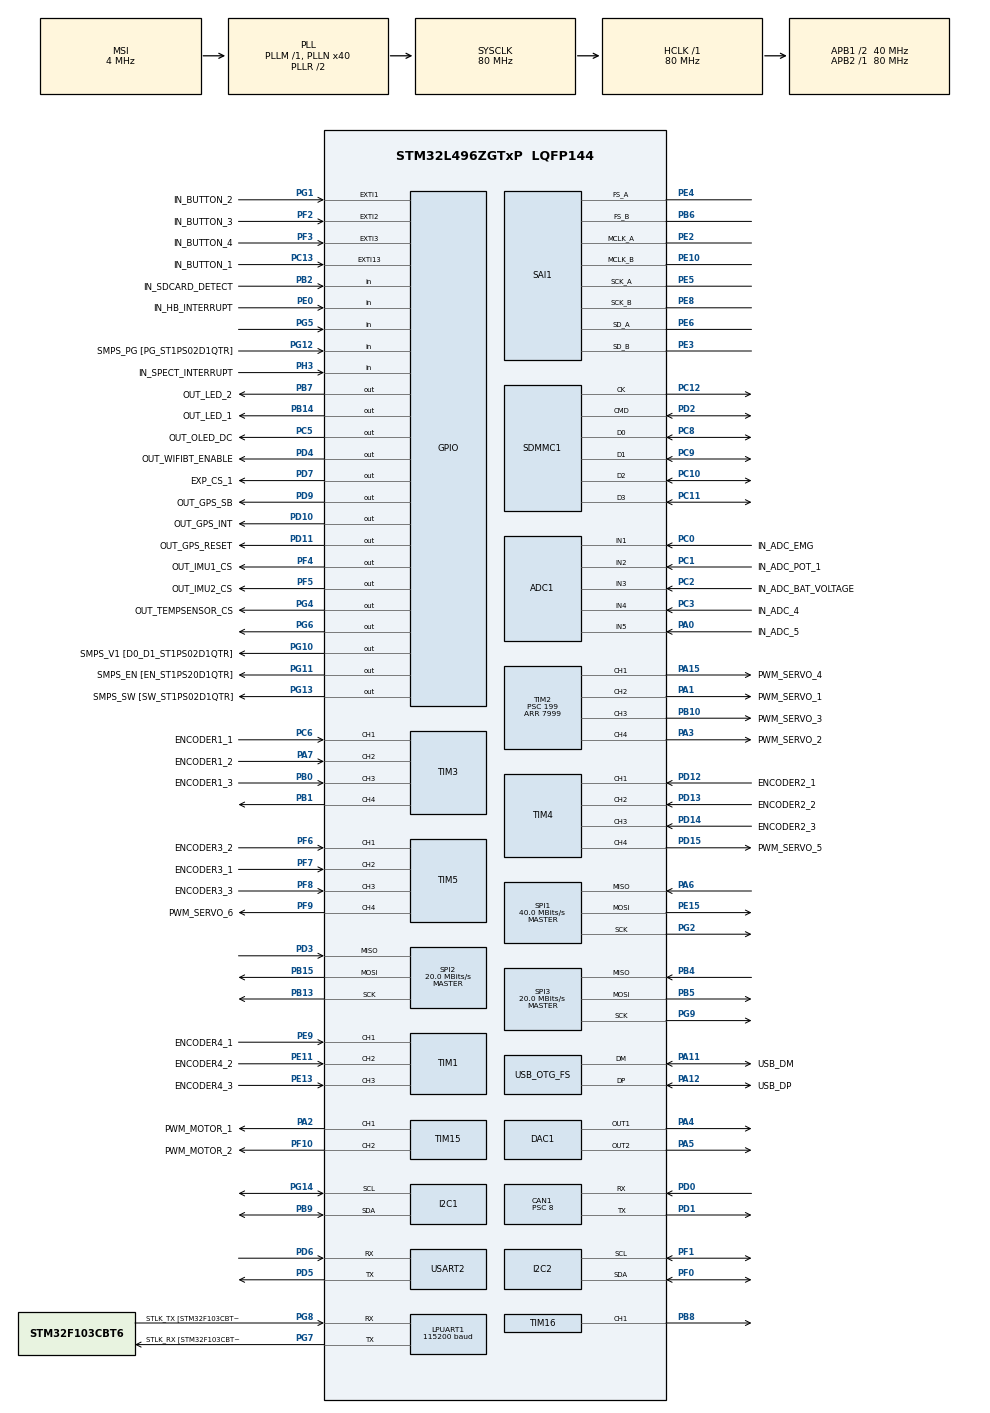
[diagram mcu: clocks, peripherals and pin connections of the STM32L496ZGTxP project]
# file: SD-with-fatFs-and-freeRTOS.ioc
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ADC1.Channel-0\#ChannelRegularConversion=ADC_CHANNEL_2
ADC1.Channel-1\#ChannelRegularConversion=ADC_CHANNEL_5
ADC1.Channel-2\#ChannelRegularConversion=ADC_CHANNEL_1
ADC1.Channel-3\#ChannelRegularConversion=ADC_CHANNEL_4
ADC1.Channel-4\#ChannelRegularConversion=ADC_CHANNEL_3
ADC1.ContinuousConvMode=ENABLE
ADC1.EOCSelection=ADC_EOC_SEQ_CONV
ADC1.NbrOfConversion=5
ADC1.NbrOfConversionFlag=1
ADC1.OffsetNumber-0\#ChannelRegularConversion=ADC_OFFSET_NONE
ADC1.OffsetNumber-1\#ChannelRegularConversion=ADC_OFFSET_NONE
ADC1.OffsetNumber-2\#ChannelRegularConversion=ADC_OFFSET_NONE
ADC1.OffsetNumber-3\#ChannelRegularConversion=ADC_OFFSET_NONE
ADC1.OffsetNumber-4\#ChannelRegularConversion=ADC_OFFSET_NONE
ADC1.OversamplingMode=ENABLE
ADC1.Rank-0\#ChannelRegularConversion=1
ADC1.Rank-1\#ChannelRegularConversion=2
ADC1.Rank-2\#ChannelRegularConversion=3
ADC1.Rank-3\#ChannelRegularConversion=4
ADC1.Rank-4\#ChannelRegularConversion=5
ADC1.Ratio=ADC_OVERSAMPLING_RATIO_8
ADC1.RightBitShift=ADC_RIGHTBITSHIFT_3
ADC1.SamplingTime-0\#ChannelRegularConversion=ADC_SAMPLETIME_2CYCLES_5
ADC1.SamplingTime-1\#ChannelRegularConversion=ADC_SAMPLETIME_2CYCLES_5
ADC1.SamplingTime-2\#ChannelRegularConversion=ADC_SAMPLETIME_2CYCLES_5
ADC1.SamplingTime-3\#ChannelRegularConversion=ADC_SAMPLETIME_2CYCLES_5
ADC1.SamplingTime-4\#ChannelRegularConversion=ADC_SAMPLETIME_2CYCLES_5
ADC1.master=1
CAN1.BS1=CAN_BS1_2TQ
CAN1.BS2=CAN_BS2_2TQ
CAN1.CalculateBaudRate=1000000
CAN1.CalculateTimeBit=1000
CAN1.CalculateTimeQuantum=200.0
CAN1.Prescaler=8
DAC1.DAC_Channel-DAC_OUT2=DAC_CHANNEL_2
Dma.ADC1.4.Direction=DMA_PERIPH_TO_MEMORY
Dma.ADC1.4.Instance=DMA1_Channel1
Dma.ADC1.4.MemDataAlignment=DMA_MDATAALIGN_WORD
Dma.ADC1.4.MemInc=DMA_MINC_ENABLE
Dma.ADC1.4.Mode=DMA_CIRCULAR
Dma.ADC1.4.PeriphDataAlignment=DMA_PDATAALIGN_WORD
Dma.ADC1.4.PeriphInc=DMA_PINC_DISABLE
Dma.ADC1.4.Priority=DMA_PRIORITY_LOW
Dma.Request0=SPI1_RX
Dma.Request1=SPI1_TX
Dma.Request2=SPI2_RX
Dma.Request3=SPI2_TX
Dma.Request4=ADC1
Dma.Request5=SDMMC1
Dma.SDMMC1.5.Direction=DMA_PERIPH_TO_MEMORY
Dma.SDMMC1.5.Instance=DMA2_Channel4
Dma.SDMMC1.5.MemDataAlignment=DMA_MDATAALIGN_WORD
Dma.SDMMC1.5.MemInc=DMA_MINC_ENABLE
Dma.SDMMC1.5.Mode=DMA_NORMAL
Dma.SDMMC1.5.PeriphDataAlignment=DMA_PDATAALIGN_WORD
Dma.SDMMC1.5.PeriphInc=DMA_PINC_DISABLE
Dma.SDMMC1.5.Priority=DMA_PRIORITY_LOW
Dma.SPI1_RX.0.Direction=DMA_PERIPH_TO_MEMORY
Dma.SPI1_RX.0.Instance=DMA1_Channel2
Dma.SPI1_RX.0.MemDataAlignment=DMA_MDATAALIGN_BYTE
Dma.SPI1_RX.0.MemInc=DMA_MINC_ENABLE
Dma.SPI1_RX.0.Mode=DMA_NORMAL
Dma.SPI1_RX.0.PeriphDataAlignment=DMA_PDATAALIGN_BYTE
Dma.SPI1_RX.0.PeriphInc=DMA_PINC_DISABLE
Dma.SPI1_RX.0.Priority=DMA_PRIORITY_LOW
Dma.SPI1_TX.1.Direction=DMA_MEMORY_TO_PERIPH
Dma.SPI1_TX.1.Instance=DMA1_Channel3
Dma.SPI1_TX.1.MemDataAlignment=DMA_MDATAALIGN_BYTE
Dma.SPI1_TX.1.MemInc=DMA_MINC_ENABLE
Dma.SPI1_TX.1.Mode=DMA_NORMAL
Dma.SPI1_TX.1.PeriphDataAlignment=DMA_PDATAALIGN_BYTE
Dma.SPI1_TX.1.PeriphInc=DMA_PINC_DISABLE
Dma.SPI1_TX.1.Priority=DMA_PRIORITY_LOW
Dma.SPI2_RX.2.Direction=DMA_PERIPH_TO_MEMORY
Dma.SPI2_RX.2.Instance=DMA1_Channel4
Dma.SPI2_RX.2.MemDataAlignment=DMA_MDATAALIGN_BYTE
Dma.SPI2_RX.2.MemInc=DMA_MINC_ENABLE
Dma.SPI2_RX.2.Mode=DMA_NORMAL
Dma.SPI2_RX.2.PeriphDataAlignment=DMA_PDATAALIGN_BYTE
Dma.SPI2_RX.2.PeriphInc=DMA_PINC_DISABLE
Dma.SPI2_RX.2.Priority=DMA_PRIORITY_LOW
Dma.SPI2_TX.3.Direction=DMA_MEMORY_TO_PERIPH
Dma.SPI2_TX.3.Instance=DMA1_Channel5
Dma.SPI2_TX.3.MemDataAlignment=DMA_MDATAALIGN_BYTE
Dma.SPI2_TX.3.MemInc=DMA_MINC_ENABLE
Dma.SPI2_TX.3.Mode=DMA_NORMAL
Dma.SPI2_TX.3.PeriphDataAlignment=DMA_PDATAALIGN_BYTE
Dma.SPI2_TX.3.PeriphInc=DMA_PINC_DISABLE
Dma.SPI2_TX.3.Priority=DMA_PRIORITY_LOW
FATFS.BSP.number=1
FATFS.USE_DMA_CODE_SD=1
FATFS._FS_RPATH=2
FATFS._USE_FIND=1
FATFS._USE_LFN=1
FATFS0.BSP.STBoard=false
FATFS0.BSP.api=Unknown
FATFS0.BSP.i2caddr=0
FATFS0.BSP.instance=PB2
FATFS0.BSP.ip=GPIO
FATFS0.BSP.mode=Input
FATFS0.BSP.name=Detect_SDIO
FATFS0.BSP.solution=PB2
I2C1.Timing=0x00909BEB
I2C2.Timing=0x00909BEB
LPUART1.BaudRate=115200
LPUART1.WordLength=UART_WORDLENGTH_8B
Mcu.Family=STM32L4
Mcu.Name=STM32L496ZGTxP
Mcu.Package=LQFP144
NVIC.CAN1_RX0_IRQn=true\:0\:0\:false\:false\:true\:true\:true
NVIC.DMA1_Channel1_IRQn=true\:0\:0\:false\:false\:true\:false\:true
NVIC.DMA1_Channel2_IRQn=true\:0\:0\:false\:false\:true\:false\:true
NVIC.DMA1_Channel3_IRQn=true\:0\:0\:false\:false\:true\:false\:true
NVIC.DMA1_Channel4_IRQn=true\:0\:0\:false\:false\:true\:false\:true
NVIC.DMA1_Channel5_IRQn=true\:0\:0\:false\:false\:true\:false\:true
NVIC.DMA2_Channel4_IRQn=true\:0\:0\:false\:false\:true\:false\:true
NVIC.EXTI15_10_IRQn=true\:0\:0\:false\:false\:true\:true\:true
NVIC.LPUART1_IRQn=true\:0\:0\:false\:false\:true\:true\:true
NVIC.PriorityGroup=NVIC_PRIORITYGROUP_4
NVIC.SDMMC1_IRQn=true\:0\:0\:false\:false\:true\:true\:true
NVIC.TIM7_IRQn=true\:0\:0\:false\:false\:true\:true\:true
PA0.GPIO_Label=IN_ADC_5
PA0.Signal=ADCx_IN5
PA1.GPIO_Label=PWM_SERVO_1
PA1.Signal=S_TIM2_CH2
PA10.GPIO_Label=USB_ID
PA10.Signal=USB_OTG_FS_ID
PA11.GPIO_Label=USB_DM
PA11.Mode=Device_Only
PA11.Signal=USB_OTG_FS_DM
PA12.GPIO_Label=USB_DP
PA12.Mode=Device_Only
PA12.Signal=USB_OTG_FS_DP
PA13\ (JTMS/SWDIO).GPIO_Label=TMS
PA13\ (JTMS/SWDIO).Mode=Trace_Asynchronous_SW
PA13\ (JTMS/SWDIO).Signal=SYS_JTMS-SWDIO
PA14\ (JTCK/SWCLK).GPIO_Label=TCK
PA14\ (JTCK/SWCLK).Mode=Trace_Asynchronous_SW
PA14\ (JTCK/SWCLK).Signal=SYS_JTCK-SWCLK
PA15\ (JTDI).GPIO_Label=PWM_SERVO_4
PA15\ (JTDI).Signal=S_TIM2_CH1
PA2.GPIO_Label=PWM_MOTOR_1
PA2.Signal=S_TIM15_CH1
PA3.GPIO_Label=PWM_SERVO_2
PA3.Signal=S_TIM2_CH4
PA4.Signal=COMP_DAC11_group
PA5.Signal=COMP_DAC12_group
PA6.Mode=Full_Duplex_Master
PA6.Signal=SPI1_MISO
PA7.GPIO_Label=ENCODER1_2
PA7.Signal=S_TIM3_CH2
PA8.GPIO_Label=USB_SOF [TP1]
PA8.Signal=USB_OTG_FS_SOF
PA9.GPIO_Label=USB_VBUS
PA9.Signal=USB_OTG_FS_VBUS
PB0.GPIO_Label=ENCODER1_3
PB0.Signal=S_TIM3_CH3
PB1.Signal=S_TIM3_CH4
PB10.GPIO_Label=PWM_SERVO_3
PB10.Signal=S_TIM2_CH3
PB13.Mode=Full_Duplex_Master
PB13.Signal=SPI2_SCK
PB14.GPIO_Label=OUT_LED_1
PB14.Signal=GPIO_Output
PB15.Mode=Full_Duplex_Master
PB15.Signal=SPI2_MOSI
PB2.GPIO_Label=IN_SDCARD_DETECT
PB2.Signal=GPIO_Input
PB3\ (JTDO/TRACESWO).GPIO_Label=SWO
PB3\ (JTDO/TRACESWO).Mode=Trace_Asynchronous_SW
PB3\ (JTDO/TRACESWO).Signal=SYS_JTDO-SWO
PB4\ (NJTRST).Mode=Full_Duplex_Master
PB4\ (NJTRST).Signal=SPI3_MISO
PB5.Mode=Full_Duplex_Master
PB5.Signal=SPI3_MOSI
PB6.Mode=SAI_B_MasterWithClock
PB6.Signal=SAI1_FS_B
PB7.GPIO_Label=OUT_LED_2
PB7.Signal=GPIO_Output
PB8.Signal=S_TIM16_CH1
PB9.GPIO_Pu=GPIO_PULLUP
PB9.Mode=I2C
PB9.Signal=I2C1_SDA
PC0.GPIO_Label=IN_ADC_EMG
PC0.Signal=ADCx_IN1
PC1.GPIO_Label=IN_ADC_POT_1
PC1.Signal=ADCx_IN2
PC10.Mode=SD_4_bits_Wide_bus
PC10.Signal=SDMMC1_D2
PC11.Mode=SD_4_bits_Wide_bus
PC11.Signal=SDMMC1_D3
PC12.Mode=SD_4_bits_Wide_bus
PC12.Signal=SDMMC1_CK
PC13.GPIO_Label=IN_BUTTON_1
PC13.Signal=GPXTI13
PC14-OSC32_IN\ (PC14).Mode=LSE-External-Oscillator
PC14-OSC32_IN\ (PC14).Signal=RCC_OSC32_IN
PC15-OSC32_OUT\ (PC15).Mode=LSE-External-Oscillator
PC15-OSC32_OUT\ (PC15).Signal=RCC_OSC32_OUT
PC2.GPIO_Label=IN_ADC_BAT_VOLTAGE
PC2.GPIO_PuPd=GPIO_NOPULL
PC2.Signal=ADCx_IN3
PC3.GPIO_Label=IN_ADC_4
PC3.Signal=ADCx_IN4
PC5.GPIO_Label=OUT_OLED_DC
PC5.Signal=GPIO_Output
PC6.GPIO_Label=ENCODER1_1
PC6.Signal=S_TIM3_CH1
PC8.Mode=SD_4_bits_Wide_bus
PC8.Signal=SDMMC1_D0
PC9.Mode=SD_4_bits_Wide_bus
PC9.Signal=SDMMC1_D1
PD0.Mode=CAN_Activate
PD0.Signal=CAN1_RX
PD1.Mode=CAN_Activate
PD1.Signal=CAN1_TX
PD10.GPIO_Label=OUT_GPS_INT
PD10.Signal=GPIO_Output
PD11.GPIO_Label=OUT_GPS_RESET
PD11.Signal=GPIO_Output
PD12.GPIO_Label=ENCODER2_1
PD12.Signal=S_TIM4_CH1
PD13.GPIO_Label=ENCODER2_2
PD13.Signal=S_TIM4_CH2
PD14.GPIO_Label=ENCODER2_3
PD14.Signal=S_TIM4_CH3
PD15.GPIO_Label=PWM_SERVO_5
PD15.Signal=S_TIM4_CH4
PD2.Mode=SD_4_bits_Wide_bus
PD2.Signal=SDMMC1_CMD
PD3.Mode=Full_Duplex_Master
PD3.Signal=SPI2_MISO
PD4.GPIO_Label=OUT_WIFIBT_ENABLE
PD4.Signal=GPIO_Output
PD5.Mode=Asynchronous
PD5.Signal=USART2_TX
PD6.Mode=Asynchronous
PD6.Signal=USART2_RX
PD7.GPIO_Label=EXP_CS_1
PD7.Signal=GPIO_Output
PD9.GPIO_Label=OUT_GPS_SB
PD9.Signal=GPIO_Output
PE0.GPIO_Label=IN_HB_INTERRUPT
PE0.Signal=GPIO_Input
PE10.Mode=SAI_B_MasterWithClock
PE10.Signal=SAI1_MCLK_B
PE11.GPIO_Label=ENCODER4_2
PE11.Signal=S_TIM1_CH2
PE13.GPIO_Label=ENCODER4_3
PE13.Signal=S_TIM1_CH3
PE15.Mode=Full_Duplex_Master
PE15.Signal=SPI1_MOSI
PE2.Mode=SAI_A_MasterWithClock
PE2.Signal=SAI1_MCLK_A
PE3.Mode=SAI_B_MasterWithClock
PE3.Signal=SAI1_SD_B
PE4.Mode=SAI_A_MasterWithClock
PE4.Signal=SAI1_FS_A
PE5.Mode=SAI_A_MasterWithClock
PE5.Signal=SAI1_SCK_A
PE6.Mode=SAI_A_MasterWithClock
PE6.Signal=SAI1_SD_A
PE8.Mode=SAI_B_MasterWithClock
PE8.Signal=SAI1_SCK_B
PE9.GPIO_Label=ENCODER4_1
PE9.Signal=S_TIM1_CH1
PF0.GPIO_Pu=GPIO_PULLUP
PF0.Mode=I2C
PF0.Signal=I2C2_SDA
PF1.GPIO_Pu=GPIO_PULLUP
PF1.Mode=I2C
PF1.Signal=I2C2_SCL
PF10.GPIO_Label=PWM_MOTOR_2
PF10.Signal=S_TIM15_CH2
PF2.GPIO_Label=IN_BUTTON_3
PF2.Signal=GPXTI2
PF3.GPIO_Label=IN_BUTTON_4
PF3.Signal=GPXTI3
PF4.GPIO_Label=OUT_IMU1_CS
PF4.Signal=GPIO_Output
PF5.GPIO_Label=OUT_IMU2_CS
PF5.Signal=GPIO_Output
PF6.GPIO_Label=ENCODER3_2
PF6.Signal=S_TIM5_CH1
PF7.GPIO_Label=ENCODER3_1
PF7.Signal=S_TIM5_CH2
PF8.GPIO_Label=ENCODER3_3
PF8.Signal=S_TIM5_CH3
PF9.GPIO_Label=PWM_SERVO_6
PF9.Signal=S_TIM5_CH4
PG1.GPIO_Label=IN_BUTTON_2
PG1.Signal=GPXTI1
PG10.GPIO_Label=SMPS_V1 [D0_D1_ST1PS02D1QTR]
PG10.Signal=GPIO_Output
PG11.GPIO_Label=SMPS_EN [EN_ST1PS20D1QTR]
PG11.Signal=GPIO_Output
PG12.GPIO_Label=SMPS_PG [PG_ST1PS02D1QTR]
PG12.Signal=GPIO_Input
PG13.GPIO_Label=SMPS_SW [SW_ST1PS02D1QTR]
PG13.Signal=GPIO_Output
PG14.GPIO_Pu=GPIO_PULLUP
PG14.Mode=I2C
PG14.Signal=I2C1_SCL
PG2.Mode=Full_Duplex_Master
PG2.Signal=SPI1_SCK
PG4.GPIO_Label=OUT_TEMPSENSOR_CS
PG4.Signal=GPIO_Output
PG5.Signal=GPIO_Input
PG6.Signal=GPIO_Output
PG7.GPIO_Label=STLK_RX [STM32F103CBT6_PA3]
PG7.Mode=Asynchronous
PG7.Signal=LPUART1_TX
PG8.GPIO_Label=STLK_TX [STM32F103CBT6_PA2]
PG8.Mode=Asynchronous
PG8.Signal=LPUART1_RX
PG9.Mode=Full_Duplex_Master
PG9.Signal=SPI3_SCK
PH0-OSC_IN\ (PH0).GPIO_Label=MCO
PH0-OSC_IN\ (PH0).Signal=RCC_OSC_IN
PH1-OSC_OUT\ (PH1).Signal=RCC_OSC_OUT
PH3-BOOT0.GPIO_Label=IN_SPECT_INTERRUPT
PH3-BOOT0.Signal=GPIO_Input
ProjectManager.HeapSize=0x400
ProjectManager.StackSize=0x800
ProjectManager.TargetToolchain=STM32CubeIDE
RCC.48MHZClocksFreq_Value=24000000
RCC.ADCFreq_Value=32000000
RCC.AHBFreq_Value=80000000
RCC.APB1CLKDivider=RCC_HCLK_DIV2
RCC.APB1Freq_Value=40000000
RCC.APB1TimFreq_Value=80000000
RCC.APB2Freq_Value=80000000
RCC.APB2TimFreq_Value=80000000
RCC.CK48CLockSelection=RCC_USBCLKSOURCE_HSI48
RCC.CortexFreq_Value=80000000
RCC.HCLKFreq_Value=80000000
RCC.HSE_VALUE=8000000
RCC.HSI48_VALUE=48000000
RCC.HSI_VALUE=16000000
RCC.MSI_VALUE=4000000
RCC.PLLMUL=RCC_PLL_MUL9
RCC.PLLN=40
RCC.PLLSAI1N=16
RCC.PRESCALERUSB=RCC_USBCLKSOURCE_PLL_DIV1_5
RCC.SYSCLKFreq_VALUE=80000000
RCC.SYSCLKSource=RCC_SYSCLKSOURCE_PLLCLK
RCC.SYSCLKSourceVirtual=RCC_SYSCLKSOURCE_PLLCLK
RCC.USBFreq_Value=48000000
RCC.VCOOutputFreq_Value=160000000
SAI1.ErrorAudioFreq-SAI_A_MasterWithClock=-2.34 %
SAI1.ErrorAudioFreq-SAI_B_MasterWithClock=-2.34 %
SAI1.InitProtocol-SAI_A_MasterWithClock=Enable
SAI1.InitProtocol-SAI_B_MasterWithClock=Enable
SAI1.Instance-SAI_A_MasterWithClock=SAI$Index_Block_A
SAI1.Instance-SAI_B_MasterWithClock=SAI$Index_Block_B
SAI1.MClockEnable-SAI_A_MasterWithClock=SAI_MASTERCLOCK_ENABLE
SAI1.MClockEnable-SAI_B_MasterWithClock=SAI_MASTERCLOCK_ENABLE
SAI1.RealAudioFreq-SAI_A_MasterWithClock=187.5 KHz
SAI1.RealAudioFreq-SAI_B_MasterWithClock=187.5 KHz
SAI1.VirtualMode-SAI_A_MasterWithClock=VM_MASTER
SAI1.VirtualMode-SAI_B_MasterWithClock=VM_MASTER
SAI1.VirtualProtocol-SAI_A_BASIC=VM_BASIC_PROTOCOL
SAI1.VirtualProtocol-SAI_B_BASIC=VM_BASIC_PROTOCOL
SDMMC1.ClockDiv=2
SH.ADCx_IN1.0=ADC1_IN1,IN1-Single-Ended
SH.ADCx_IN2.0=ADC1_IN2,IN2-Single-Ended
SH.ADCx_IN3.0=ADC1_IN3,IN3-Single-Ended
SH.ADCx_IN4.0=ADC1_IN4,IN4-Single-Ended
SH.ADCx_IN5.0=ADC1_IN5,IN5-Single-Ended
SH.COMP_DAC11_group.0=DAC1_OUT1,DAC_OUT1
SH.COMP_DAC12_group.0=DAC1_OUT2,DAC_OUT2
SH.S_TIM15_CH1.0=TIM15_CH1,PWM Generation1 CH1
SH.S_TIM15_CH2.0=TIM15_CH2,PWM Generation2 CH2
SH.S_TIM16_CH1.0=TIM16_CH1,PWM Generation1 CH1
SH.S_TIM1_CH1.0=TIM1_CH1,Xored_Inputs_Hall_Sensor_Interface
SH.S_TIM1_CH2.0=TIM1_CH2,Xored_Inputs_Hall_Sensor_Interface
SH.S_TIM1_CH3.0=TIM1_CH3,Xored_Inputs_Hall_Sensor_Interface
SH.S_TIM2_CH1.0=TIM2_CH1,PWM Generation1 CH1
SH.S_TIM2_CH2.0=TIM2_CH2,PWM Generation2 CH2
SH.S_TIM2_CH3.0=TIM2_CH3,PWM Generation3 CH3
SH.S_TIM2_CH4.0=TIM2_CH4,PWM Generation4 CH4
SH.S_TIM3_CH1.0=TIM3_CH1,Xored_Inputs_Hall_Sensor_Interface
SH.S_TIM3_CH2.0=TIM3_CH2,Xored_Inputs_Hall_Sensor_Interface
SH.S_TIM3_CH3.0=TIM3_CH3,Xored_Inputs_Hall_Sensor_Interface
SH.S_TIM3_CH4.0=TIM3_CH4,PWM Generation4 CH4
SH.S_TIM4_CH1.0=TIM4_CH1,Xored_Inputs_Hall_Sensor_Interface
SH.S_TIM4_CH2.0=TIM4_CH2,Xored_Inputs_Hall_Sensor_Interface
SH.S_TIM4_CH3.0=TIM4_CH3,Xored_Inputs_Hall_Sensor_Interface
SH.S_TIM4_CH4.0=TIM4_CH4,PWM Generation4 CH4
SH.S_TIM5_CH1.0=TIM5_CH1,Xored_Inputs_Hall_Sensor_Interface
SH.S_TIM5_CH2.0=TIM5_CH2,Xored_Inputs_Hall_Sensor_Interface
SH.S_TIM5_CH3.0=TIM5_CH3,Xored_Inputs_Hall_Sensor_Interface
SH.S_TIM5_CH4.0=TIM5_CH4,PWM Generation4 CH4
SPI1.CalculateBaudRate=40.0 MBits/s
SPI1.Direction=SPI_DIRECTION_2LINES
SPI1.Mode=SPI_MODE_MASTER
SPI1.VirtualType=VM_MASTER
SPI2.CalculateBaudRate=20.0 MBits/s
SPI2.Direction=SPI_DIRECTION_2LINES
SPI2.Mode=SPI_MODE_MASTER
SPI2.VirtualType=VM_MASTER
SPI3.CalculateBaudRate=20.0 MBits/s
SPI3.Direction=SPI_DIRECTION_2LINES
SPI3.Mode=SPI_MODE_MASTER
SPI3.VirtualType=VM_MASTER
TIM15.Channel-PWM\ Generation1\ CH1=TIM_CHANNEL_1
TIM15.Channel-PWM\ Generation2\ CH2=TIM_CHANNEL_2
TIM16.Channel=TIM_CHANNEL_1
TIM2.AutoReloadPreload=TIM_AUTORELOAD_PRELOAD_DISABLE
TIM2.Channel-PWM\ Generation1\ CH1=TIM_CHANNEL_1
TIM2.Channel-PWM\ Generation2\ CH2=TIM_CHANNEL_2
TIM2.Channel-PWM\ Generation3\ CH3=TIM_CHANNEL_3
TIM2.Channel-PWM\ Generation4\ CH4=TIM_CHANNEL_4
TIM2.Period=7999
TIM2.Prescaler=199
TIM3.Channel-PWM\ Generation4\ CH4=TIM_CHANNEL_4
TIM4.Channel-PWM\ Generation4\ CH4=TIM_CHANNEL_4
TIM5.Channel-PWM\ Generation4\ CH4=TIM_CHANNEL_4
TIM7.AutoReloadPreload=TIM_AUTORELOAD_PRELOAD_ENABLE
TIM7.Period=39999
USART2.VirtualMode-Asynchronous=VM_ASYNC
USB_OTG_FS.VirtualMode=Device_Only
VP_FATFS_VS_SDIO.Mode=SDIO
VP_RTC_VS_RTC_Activate.Mode=RTC_Enabled
VP_SAI1_VP_$IpInstance_SAIA_SAI_BASIC.Mode=SAI_A_BASIC
VP_SAI1_VP_$IpInstance_SAIB_SAI_BASIC.Mode=SAI_B_BASIC
VP_TIM16_VS_ClockSourceINT.Mode=Enable_Timer
VP_TIM2_VS_ClockSourceINT.Mode=Internal
VP_TIM7_VS_ClockSourceINT.Mode=Enable_Timer
board=NUCLEO-L496ZG-P

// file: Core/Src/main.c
/* USER CODE BEGIN Header */
/**
  ******************************************************************************
  * @file           : main.c
  * @brief          : Main program body
  ******************************************************************************
  * @attention
  *
  * <h2><center>&copy; Copyright (c) 2021 STMicroelectronics.
  * All rights reserved.</center></h2>
  *
  * This software component is licensed by ST under Ultimate Liberty license
  * SLA0044, the "License"; You may not use this file except in compliance with
  * the License. You may obtain a copy of the License at:
  *                             www.st.com/SLA0044
  *
  ******************************************************************************
  */
/* USER CODE END Header */
#include "main.h"
#include "adc.h"
#include "can.h"
#include "dac.h"
#include "dma.h"
#include "fatfs.h"
#include "i2c.h"
#include "usart.h"
#include "rtc.h"
#include "sai.h"
#include "sdmmc.h"
#include "spi.h"
#include "tim.h"
#include "usb_otg.h"
#include "gpio.h"

/* USER CODE BEGIN Includes */
#include <string.h>
/* USER CODE END Includes */

void SystemClock_Config(void);
void PeriphCommonClock_Config(void);
/* USER CODE BEGIN PFP */
//DMAFIX todo1: Create config functions for rx and tx dma
static HAL_StatusTypeDef SD_DMAConfigRx(SD_HandleTypeDef *hsd);
static HAL_StatusTypeDef SD_DMAConfigTx(SD_HandleTypeDef *hsd);
/* USER CODE END PFP */

int main(void)
{
  /* USER CODE BEGIN 1 */
	FRESULT resu; /* FatFs function common result code */
	uint32_t byteswritten;
	uint8_t wtext[] = "Ceci est un exemple d'écriture sur une carte SD!"; /* File write buffer */
	uint8_t rtext[_MAX_SS];/* File read buffer */
  /* USER CODE END 1 */

  /* MCU Configuration--------------------------------------------------------*/

  /* Reset of all peripherals, Initializes the Flash interface and the Systick. */
  HAL_Init();

  /* Configure the system clock */
  SystemClock_Config();

/* Configure the peripherals common clocks */
  PeriphCommonClock_Config();

  /* Initialize all configured peripherals */
  MX_GPIO_Init();
  MX_DMA_Init();
  MX_LPUART1_UART_Init();
  MX_SPI1_Init();
  MX_SPI2_Init();
  MX_ADC1_Init();
  MX_I2C1_Init();
  MX_RTC_Init();
  MX_SAI1_Init();
  MX_SDMMC1_SD_Init();
  MX_TIM2_Init();
  MX_TIM3_Init();
  MX_TIM4_Init();
  MX_TIM5_Init();
  MX_TIM15_Init();
  MX_USB_OTG_FS_PCD_Init();
  MX_I2C2_Init();
  MX_USART2_UART_Init();
  MX_SPI3_Init();
  MX_TIM1_Init();
  MX_TIM16_Init();
  MX_DAC1_Init();
  MX_CAN1_Init();
  MX_FATFS_Init();
  MX_TIM7_Init();
  /* USER CODE BEGIN 2 */

    resu = f_mount(&SDFatFS, (TCHAR const*)SDPath, 1);
    if( resu != FR_OK)
    	{
    		//Error_Handler();
  	  	if(resu == FR_NO_FILESYSTEM)
  	  	{
  	  		resu = f_mkfs((TCHAR const*)SDPath, FM_FAT32, 0, rtext, sizeof(rtext));
  			if( resu != FR_OK)
  			{
  				Error_Handler();
  			}
  	  	}
  	  	else
  	  	{
  	  		Error_Handler();
  	  	}

    	}

  		resu = f_mount(&SDFatFS, (TCHAR const*)SDPath, 1);
  		if(resu != FR_OK)
  		{
  			Error_Handler();
  		}
  		else
  		{
  			//Open file for writing (Create)
  			resu = f_open(&SDFile, "STM32.TXT", FA_CREATE_ALWAYS | FA_WRITE);
  			if( resu != FR_OK)
  			{
  				Error_Handler();
  			}
  			else
  			{
  				//HAL_GPIO_WritePin(OUT_D0_GPIO_Port, OUT_D0_Pin, 1); // Utiliser pour mesure le temps d'execution avec un analyseur logique
  				//Write to the text file
  				resu = f_write(&SDFile, wtext, strlen((char *)wtext), (void *)&byteswritten);

  				//HAL_GPIO_WritePin(OUT_D0_GPIO_Port, OUT_D0_Pin, 0); // Utiliser pour mesure le temps d'execution avec un analyseur logique

  				if((byteswritten == 0) || (resu != FR_OK))
  				{
  					Error_Handler();
  				}
  				else
  				{
  					f_close(&SDFile);
  				}
  			}

  			f_mount(&SDFatFS, (TCHAR const*)NULL, 0); // unmount
  		}

  /* USER CODE END 2 */

  /* Infinite loop */
  while (1)
  {

  }
}

void SystemClock_Config(void)
{
  RCC_OscInitTypeDef RCC_OscInitStruct = {0};
  RCC_ClkInitTypeDef RCC_ClkInitStruct = {0};

  /** Configure the main internal regulator output voltage
  */
  if (HAL_PWREx_ControlVoltageScaling(PWR_REGULATOR_VOLTAGE_SCALE1) != HAL_OK)
  {
    Error_Handler();
  }
  /** Initializes the RCC Oscillators according to the specified parameters
  * in the RCC_OscInitTypeDef structure.
  */
  RCC_OscInitStruct.OscillatorType = RCC_OSCILLATORTYPE_HSI48|RCC_OSCILLATORTYPE_LSI
                              |RCC_OSCILLATORTYPE_MSI;
  RCC_OscInitStruct.HSI48State = RCC_HSI48_ON;
  RCC_OscInitStruct.LSIState = RCC_LSI_ON;
  RCC_OscInitStruct.MSIState = RCC_MSI_ON;
  RCC_OscInitStruct.MSICalibrationValue = 0;
  RCC_OscInitStruct.MSIClockRange = RCC_MSIRANGE_6;
  RCC_OscInitStruct.PLL.PLLState = RCC_PLL_ON;
  RCC_OscInitStruct.PLL.PLLSource = RCC_PLLSOURCE_MSI;
  RCC_OscInitStruct.PLL.PLLM = 1;
  RCC_OscInitStruct.PLL.PLLN = 40;
  RCC_OscInitStruct.PLL.PLLP = RCC_PLLP_DIV2;
  RCC_OscInitStruct.PLL.PLLQ = RCC_PLLQ_DIV2;
  RCC_OscInitStruct.PLL.PLLR = RCC_PLLR_DIV2;
  if (HAL_RCC_OscConfig(&RCC_OscInitStruct) != HAL_OK)
  {
    Error_Handler();
  }
  /** Initializes the CPU, AHB and APB buses clocks
  */
  RCC_ClkInitStruct.ClockType = RCC_CLOCKTYPE_HCLK|RCC_CLOCKTYPE_SYSCLK
                              |RCC_CLOCKTYPE_PCLK1|RCC_CLOCKTYPE_PCLK2;
  RCC_ClkInitStruct.SYSCLKSource = RCC_SYSCLKSOURCE_PLLCLK;
  RCC_ClkInitStruct.AHBCLKDivider = RCC_SYSCLK_DIV1;
  RCC_ClkInitStruct.APB1CLKDivider = RCC_HCLK_DIV2;
  RCC_ClkInitStruct.APB2CLKDivider = RCC_HCLK_DIV1;

  if (HAL_RCC_ClockConfig(&RCC_ClkInitStruct, FLASH_LATENCY_4) != HAL_OK)
  {
    Error_Handler();
  }
}

void PeriphCommonClock_Config(void)
{
  RCC_PeriphCLKInitTypeDef PeriphClkInit = {0};

  /** Initializes the peripherals clock
  */
  PeriphClkInit.PeriphClockSelection = RCC_PERIPHCLK_SAI1|RCC_PERIPHCLK_ADC;
  PeriphClkInit.Sai1ClockSelection = RCC_SAI1CLKSOURCE_PLLSAI1;
  PeriphClkInit.AdcClockSelection = RCC_ADCCLKSOURCE_PLLSAI1;
  PeriphClkInit.PLLSAI1.PLLSAI1Source = RCC_PLLSOURCE_MSI;
  PeriphClkInit.PLLSAI1.PLLSAI1M = 1;
  PeriphClkInit.PLLSAI1.PLLSAI1N = 16;
  PeriphClkInit.PLLSAI1.PLLSAI1P = RCC_PLLP_DIV2;
  PeriphClkInit.PLLSAI1.PLLSAI1Q = RCC_PLLQ_DIV2;
  PeriphClkInit.PLLSAI1.PLLSAI1R = RCC_PLLR_DIV2;
  PeriphClkInit.PLLSAI1.PLLSAI1ClockOut = RCC_PLLSAI1_SAI1CLK|RCC_PLLSAI1_ADC1CLK;
  if (HAL_RCCEx_PeriphCLKConfig(&PeriphClkInit) != HAL_OK)
  {
    Error_Handler();
  }
}

/* USER CODE BEGIN 4 */

/**
  * @brief Configure the DMA to receive data from the SD card
  * @retval
  *  HAL_ERROR or HAL_OK
  */
static HAL_StatusTypeDef SD_DMAConfigRx(SD_HandleTypeDef *hsd)
{
  static DMA_HandleTypeDef hdma_rx;
  HAL_StatusTypeDef status = HAL_ERROR;

  /* Configure DMA Rx parameters */
  hdma_rx.Init.Request             = DMA_REQUEST_7;
  hdma_rx.Init.Direction           = DMA_PERIPH_TO_MEMORY;
  hdma_rx.Init.PeriphInc           = DMA_PINC_DISABLE;
  hdma_rx.Init.MemInc              = DMA_MINC_ENABLE;
  hdma_rx.Init.PeriphDataAlignment = DMA_PDATAALIGN_WORD;
  hdma_rx.Init.MemDataAlignment    = DMA_MDATAALIGN_WORD;
  hdma_rx.Init.Priority            = DMA_PRIORITY_VERY_HIGH;

  hdma_rx.Instance = DMA2_Channel4;

  /* Associate the DMA handle */
  __HAL_LINKDMA(hsd, hdmarx, hdma_rx);

  /* Stop any ongoing transfer and reset the state*/
  HAL_DMA_Abort(&hdma_rx);

  /* Deinitialize the Channel for new transfer */
  HAL_DMA_DeInit(&hdma_rx);

  /* Configure the DMA Channel */
  status = HAL_DMA_Init(&hdma_rx);

  /* NVIC configuration for DMA transfer complete interrupt */
  HAL_NVIC_SetPriority(DMA2_Channel4_IRQn, 6, 0);
  HAL_NVIC_EnableIRQ(DMA2_Channel4_IRQn);

  return (status);
}

//DMAFIX todo1: Create config functions for rx and tx dma
/**
  * @brief Configure the DMA to transmit data to the SD card
  * @retval
  *  HAL_ERROR or HAL_OK
  */
static HAL_StatusTypeDef SD_DMAConfigTx(SD_HandleTypeDef *hsd)
{
  static DMA_HandleTypeDef hdma_tx;
  HAL_StatusTypeDef status;

  /* Configure DMA Tx parameters */
  hdma_tx.Init.Request             = DMA_REQUEST_7;
  hdma_tx.Init.Direction           = DMA_MEMORY_TO_PERIPH;
  hdma_tx.Init.PeriphInc           = DMA_PINC_DISABLE;
  hdma_tx.Init.MemInc              = DMA_MINC_ENABLE;
  hdma_tx.Init.PeriphDataAlignment = DMA_PDATAALIGN_WORD;
  hdma_tx.Init.MemDataAlignment    = DMA_MDATAALIGN_WORD;
  hdma_tx.Init.Priority            = DMA_PRIORITY_VERY_HIGH;

  hdma_tx.Instance = DMA2_Channel4;

  /* Associate the DMA handle */
  __HAL_LINKDMA(hsd, hdmatx, hdma_tx);

  /* Stop any ongoing transfer and reset the state*/
  HAL_DMA_Abort(&hdma_tx);

  /* Deinitialize the Channel for new transfer */
  HAL_DMA_DeInit(&hdma_tx);

  /* Configure the DMA Channel */
  status = HAL_DMA_Init(&hdma_tx);

  /* NVIC configuration for DMA transfer complete interrupt */
  HAL_NVIC_SetPriority(DMA2_Channel4_IRQn, 6, 0);
  HAL_NVIC_EnableIRQ(DMA2_Channel4_IRQn);

  return (status);
}

//DMAFIX todo 2: Override DMA write functions
uint8_t BSP_SD_WriteBlocks_DMA(uint32_t *pData, uint32_t WriteAddr, uint32_t NumOfBlocks)
{
  uint8_t sd_state = MSD_OK;

  // Invalidate the dma rx handle
  hsd1.hdmarx = NULL;

  // Prepare the dma channel for a read operation
  sd_state = SD_DMAConfigTx(&hsd1);

  if(sd_state == HAL_OK)
  {
    /* Write block(s) in DMA transfer mode */
    sd_state = HAL_SD_WriteBlocks_DMA(&hsd1, (uint8_t *)pData, WriteAddr, NumOfBlocks);
  }

  if( sd_state == HAL_OK)
  {
    return MSD_OK;
  }
  else
  {
    return MSD_ERROR;
  }

  return sd_state;
}

//DMAFIX todo 3: Override DMA read functions
uint8_t BSP_SD_ReadBlocks_DMA(uint32_t *pData, uint32_t ReadAddr, uint32_t NumOfBlocks)
{
  uint8_t sd_state = MSD_OK;
  /* Invalidate the dma tx handle*/
  hsd1.hdmatx = NULL;

  /* Prepare the dma channel for a read operation */
  sd_state = SD_DMAConfigRx(&hsd1);

  if(sd_state == HAL_OK)
  {
	   /* Read block(s) in DMA transfer mode */
	    sd_state = HAL_SD_ReadBlocks_DMA(&hsd1, (uint8_t *)pData, ReadAddr, NumOfBlocks);
  }

  if( sd_state == HAL_OK)
  {
	return MSD_OK;
  }
  else
  {
	return MSD_ERROR;
  }
}

/* USER CODE END 4 */

void Error_Handler(void)
{
  __disable_irq();
  while (1)
  {
  }
}
